# f28004x_gpio_data_regs register map
Vendor: Texas Instruments
Peripheral module from a debugger description file (folder C2000).
Address unit: 16 bits
Registers are 32-bit, read-write, no defined reset value unless marked. A register's access mark holds for its fields unless they carry their own. Offsets are as the file gives them; lines under a group give offsets from that group; [hi:lo] are bit positions; {n}, {i} and the like mark numbered series; 'fields as' and 'values as' point back to an identical list; <NAME> marks a mode.

## GPIO_DATA_REGS — GPIO DATA Registers
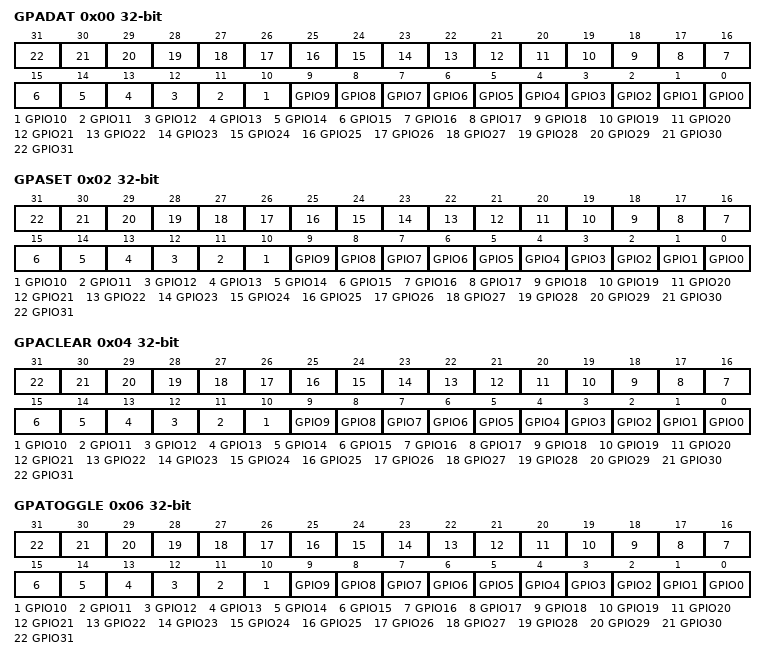
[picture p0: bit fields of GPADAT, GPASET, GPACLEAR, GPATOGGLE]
0x00 GPADAT — GPIO A Data Register (GPIO0 to GPIO31)
  [n] GPIO{n} (n=0..31) — Data Register for this pin
0x02 GPASET — GPIO A Output Set (GPIO0 to GPIO31)
  [n] GPIO{n} (n=0..31) — Output Set bit for this pin
0x04 GPACLEAR — GPIO A Output Clear (GPIO0 to GPIO31)
  [n] GPIO{n} (n=0..31) — Output Clear bit for this pin
0x06 GPATOGGLE — GPIO A Output Toggle (GPIO0 to GPIO31)
  [n] GPIO{n} (n=0..31) — Output Toggle bit for this pin
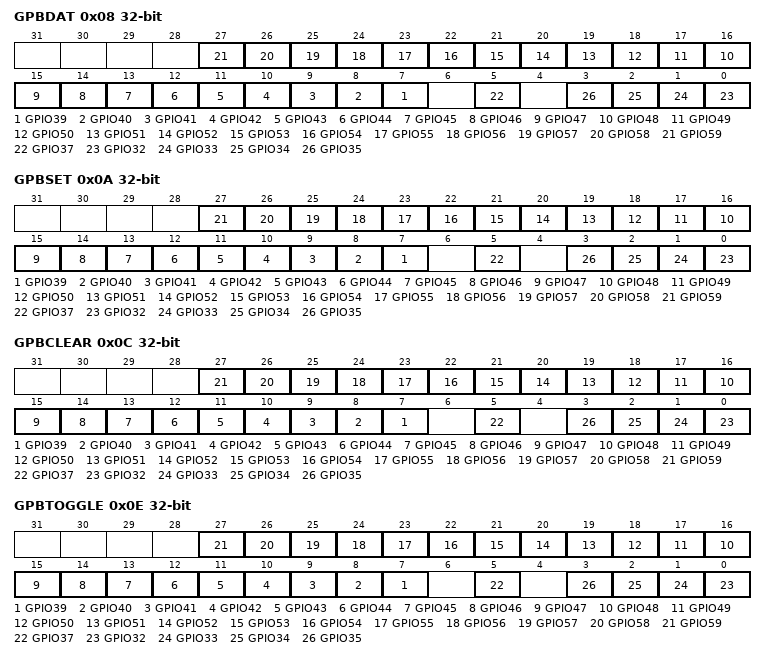
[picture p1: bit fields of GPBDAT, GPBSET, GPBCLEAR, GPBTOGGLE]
0x08 GPBDAT — GPIO B Data Register (GPIO32 to GPIO64)
  [n-32] GPIO{n} (n=39..59) — Data Register for this pin
  [5] GPIO37 — Data Register for this pin
  [n-32] GPIO{n} (n=32..35) — Data Register for this pin
0x0A GPBSET — GPIO B Output Set (GPIO32 to GPIO64)
  [n-32] GPIO{n} (n=39..59) — Output Set bit for this pin
  [5] GPIO37 — Output Set bit for this pin
  [n-32] GPIO{n} (n=32..35) — Output Set bit for this pin
0x0C GPBCLEAR — GPIO B Output Clear (GPIO32 to GPIO64)
  [n-32] GPIO{n} (n=39..59) — Output Clear bit for this pin
  [5] GPIO37 — Output Clear bit for this pin
  [n-32] GPIO{n} (n=32..35) — Output Clear bit for this pin
0x0E GPBTOGGLE — GPIO B Output Toggle (GPIO32 to GPIO64)
  [n-32] GPIO{n} (n=39..59) — Output Toggle bit for this pin
  [5] GPIO37 — Output Toggle bit for this pin
  [n-32] GPIO{n} (n=32..35) — Output Toggle bit for this pin
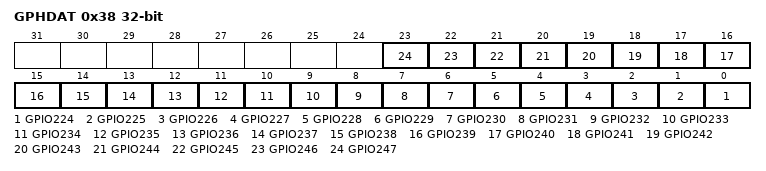
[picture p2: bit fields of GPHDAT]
0x38 GPHDAT — GPIO H Data Register (GPIO0 to GPIO255)
  [n-224] GPIO{n} (n=224..247) — Data Register for this pin
